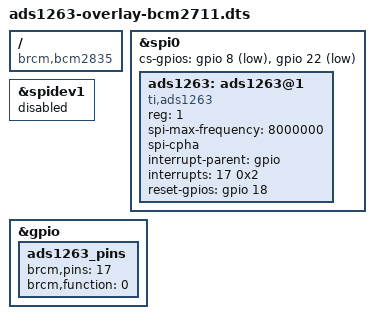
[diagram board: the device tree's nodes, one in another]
/*
 * Device tree overlay for ads1263 on spi0.1
 */

/dts-v1/;
/plugin/;

/ {
    compatible = "brcm,bcm2835";

    /* https://gist.github.com/mcbridejc/d060602e892f6879e7bc8b93aa3f85be */
    fragment@0 {
        target = <&spi0>;
        __overlay__ {
            status = "okay";
            cs-gpios = <&gpio 8 1>, <&gpio 22 1>;
        };
    };

    /* disable spi-dev for spi0.1 */
    fragment@1 {
        target = <&spidev1>;
        __overlay__ {
            status = "disabled";
        };
    };

    /* the drdy pin */
    fragment@2 {
        target = <&gpio>;
        __overlay__ {
            ads1263_pins: ads1263_pins {
                brcm,pins = <17>;
                brcm,function = <0>; /* input */
            };
        };
    };

    fragment@3 {
        target = <&spi0>;
        __overlay__ {
            /* needed to avoid dtc warning */
            #address-cells = <1>;
            #size-cells = <0>;
            ads1263: ads1263@1 {
                compatible = "ti,ads1263";
                reg = <1>;                
                spi-max-frequency = <8000000>;
                spi-cpha;
                
                interrupt-parent = <&gpio>;
                interrupts = <17 0x2>;

                reset-gpios = <&gpio 18 0>;
            };
        };
    };

    __overrides__ {
        spimaxfrequency = <&ads1263>,"spi-max-frequency:0";
        interrupt = <&ads1263_pins>,"brcm,pins:0",<&ads1263>,"interrupts:0";
    };
};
